# STM32WBA54 register map
File version: 1.0
CPU: CM33 r0p1, little endian, MPU, FPU, 4 interrupt priority bits
Registers are 32-bit, read-write, reset 0x0 unless marked. A register's access mark holds for its fields unless they carry their own. Offsets are from the block's base; [hi:lo] are bit positions; {n}, {i} and the like mark numbered series.

## HSEM — Hardware semaphore
Base 0x420C1C00
Same registers: SEC_HSEM 0x520C1C00
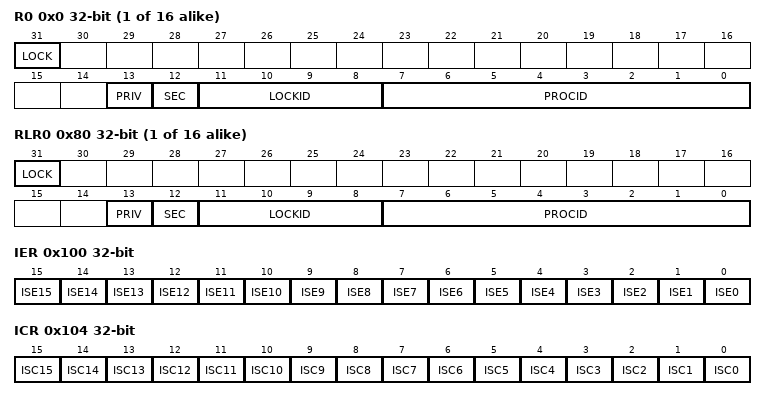
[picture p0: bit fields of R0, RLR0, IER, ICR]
{0x0+4i} R{i} (i=0..15) — HSEM register HSEM_R{i}
  [31] LOCK — Lock indication This bit can be written and read by software.
  [13] PRIV — Semaphore privilege Written by software - When the semaphore is free and the LOCK bit is at the same time written to 1, and the LOCKID matches the AHB bus master ID, SEC and PRIV matches the AHB bus master definition. - When the semaphore is unlocked (LOCK written to 0 and AHB bus master ID matched LOCKID, SEC and PRIV matches the AHB bus master definition, the PRIV is cleared to 0. - When the semaphore is unlocked (LOCK bit written to 0 and AHB bus master ID does not match LOCKID and/or SEC or PRIV do not match AHB bus master definition, the PRIV is not affected. - Write when LOCK bit is already 1 (semaphore locked), the PRIV is not affected. - An authorized read returns the stored PRIV value.
  [12] SEC — Semaphore secure Written by software - When the semaphore is free and the LOCK bit is at the same time written to 1, and the LOCKID matches the AHB bus master ID, SEC and PRIV matches the AHB bus master definition. - When the semaphore is unlocked (LOCK written to 0 and AHB bus master ID matched LOCKID, SEC and PRIV matches the AHB bus master definition, the SEC is cleared to 0. - When the semaphore is unlocked (LOCK bit written to 0 and AHB bus master ID does not match LOCKID and/or SEC or PRIV do not match AHB bus master definition, the SEC is not affected. - Write when LOCK bit is already 1 (semaphore locked), the SEC is not affected. - An authorized read returns the stored SEC value.
  [11:8] LOCKID — Semaphore LOCKID Written by software - When the semaphore is free and the LOCK bit is at the same time written to 1 and the LOCKID matches the AHB bus master ID, SEC and PRIV matches the AHB bus master protection. - When the semaphore is unlocked (LOCK written to 0 and AHB bus master ID matched LOCKID, SEC and PRIV matches the AHB bus master protection, the LOCKID is cleared to 0. - When the semaphore is unlocked (LOCK bit written to 0 or AHB bus master ID does not match LOCKID and/or SEC or PRIV do not match AHB bus master protection, the LOCKID is not affected. - Write when LOCK bit is already 1 (semaphore locked), the LOCKID is not affected. - An authorized read returns the stored LOCKID value.
  [7:0] PROCID — Semaphore PROCID Written by software -When the semaphore is free and the LOCK is written to 1, and the LOCKID matches the AHB bus master ID, SEC and PRIV matches the AHB bus master definition, PROCID is set to the written data. - When the semaphore is unlocked, LOCK written to 0 and AHB bus master ID matched LOCKID, SEC and PRIV matches the AHB bus master protection, the PROCID is cleared to 0. - When the semaphore is unlocked, LOCK bit written to 0 and AHB bus master ID does not match LOCKID and/or SEC or PRIV do not match the AHB bus master definition, the PROCID is not affected. - Write when LOCK bit is already 1 (semaphore locked), the PROCID is not affected. - An authorized read returns the stored PROCID value.
{0x80+4i} RLR{i} (i=0..15) ro — Semaphore {i} read lock register
  [31] LOCK — Lock indication This bit is read only by software at this address. - When the semaphore is free: A read with a valid AHB bus master ID and SEC and PRIV locks the semaphore and returns 1. - When the semaphore is locked: A read with a valid AHB bus master ID and SEC and PRIV returns 1 (the LOCKID and SEC and PRIV and PROCID reflect the already locked semaphore information).
  [13] PRIV — Semaphore privilege This field is read only by software at this address. - When the semaphore is free: A read with a valid AHB bus master ID and SEC and PRIV locks the semaphore and hardware sets the PRIV to the valid AHB bus master privileged definition. - When the semaphore is locked: A read with a valid AHB bus master ID and SEC and PRIV returns the PRIV of the AHB bus master that has locked the semaphore.
  [12] SEC — Semaphore secure. This field is read only by software at this address. - When the semaphore is free: A read with a valid AHB bus master ID and SEC and PRIV locks the semaphore and hardware sets the SEC to the valid AHB bus master security definition. - When the semaphore is locked: A read with a valid AHB bus master ID and SEC and PRIV returns the SEC of the AHB bus master that has locked the semaphore.
  [11:8] LOCKID — Semaphore LOCKID This field is read only by software at this address. On a read, when the semaphore is free, the hardware sets the LOCKID to the AHB bus master ID reading the semaphore. The LOCKID of the AHB bus master locking the semaphore is read. On a read when the semaphore is locked, this field returns the LOCKID of the AHB bus master that has locked the semaphore.
  [7:0] PROCID — Semaphore processor ID This field is read only by software at this address. - On a read when the semaphore is free: A read with a valid AHB bus master ID and SEC and PRIV locks the semaphore and hardware sets the PROCID to 0. - When the semaphore is locked: A read with a valid AHB bus master ID and SEC and PRIV returns the PROCID of the AHB bus master that has locked the semaphore.
0x100 IER access not given — HSEM non-secure interrupt enable register
  [n] ISE{n} (n=0..15) — Interrupt semaphore {n} enable bit
0x104 ICR access not given — HSEM non-secure interrupt clear register
  [n] ISC{n} (n=0..15) — Interrupt semaphore {n} clear bit
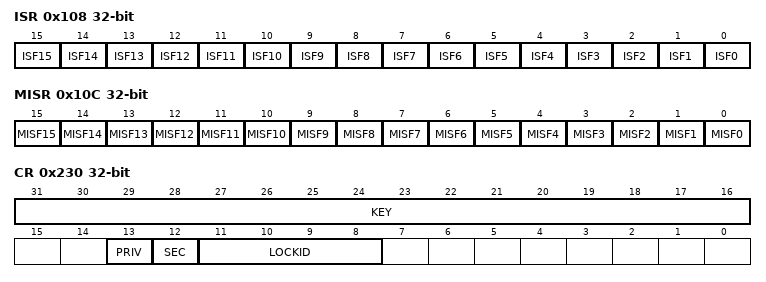
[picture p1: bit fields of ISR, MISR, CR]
0x108 ISR access not given — HSEM non-secure interrupt status register
  [n] ISF{n} (n=0..15) — Interrupt semaphore {n} status bit before enable (mask)
0x10C MISR access not given — HSEM non-secure interrupt status register
  [n] MISF{n} (n=0..15) — Masked interrupt semaphore {n} status bit after enable (mask)
0x180 SIER — HSEM secure interrupt enable register
  [15:0] SISE — Secure interrupt semaphore x enable bit This bit is read and written by software. When semaphore x PRIVx is disabled, bit x can be accessed with secure privilege and secure unprivileged access. When semaphore x PRIVx is enabled, bit x can be accessed only with secure privilege access. secure unprivileged write to this bit is discarded, secure unprivileged read return 0 value.
0x184 SICR — HSEM secure interrupt clear register
  [15:0] SISC — Secure interrupt semaphore x clear bit This bit is written by software, and is always read 0. When semaphore x PRIVx is disabled, bit x can be accessed with secure privilege and secure unprivileged access. When semaphore x PRIVx is enabled, bit x can be accessed only with secure privilege access. Secure unprivileged write to this bit is discarded.
0x188 SISR ro — HSEM secure interrupt status register
  [15:0] SISF — Secure interrupt semaphore x status bit before enable (mask) This bit is set by hardware and read only by software. Bit is cleared by software writing the corresponding HSEM_SCnICR bit x. When semaphore x PRIVx is disabled, bit x can be accessed with secure privilege and secure unprivileged access. When semaphore x PRIVx is enabled, bit x can be accessed only with secure privilege access. Secure unprivileged read return 0 value.
0x18C MSISR ro — HSEM secure masked interrupt status register
  [15:0] SMISF — Secure masked interrupt semaphore x status bit after enable (mask) This bit is set by hardware and read only by software. Bit is cleared by software writing the corresponding HSEM_SCnICR bit x. Bit is read as 0 when semaphore x status is masked in HSEM_SCnIER bit x. When semaphore x PRIVx is disabled, bit x can be accessed with secure privilege and secure unprivileged access. When semaphore x PRIVx is enabled, bit x can be accessed only with secure privilege access. Secure unprivileged read return 0 value.
0x200 SECCFGR — HSEM security configuration register
  [15:0] SEC — Semaphore x security attribute This bit is set and cleared by software.
0x210 PRIVCFGR — HSEM privilege configuration register
  [15:0] PRIV — Semaphore x privilege attribute This bit is set and cleared by software. When semaphore x SECx is disabled, bit x can be write accessed with secure privileged and non-secure privileged access. When semaphore x SECx is enabled, bit x can only be write accessed with secure privilege access. Non-secure privileged write access is discarded. Both secure and non-secure read return the register bit x value
0x230 CR wo — HSEM clear register
  [31:16] KEY — Semaphore clear key This field can be written by software and is always read 0. If this key value does not match HSEM_KEYR.KEY, semaphores are not affected. If this key value matches HSEM_KEYR.KEY, all semaphores matching the LOCKID are cleared to the free state.
  [13] PRIV — PRIV value of semaphores to be cleared. This field can be written by software, is always read 0. Indicates the PRIV for which the CID semaphores are cleared when writing the HSEM_CR.
  [12] SEC — SEC value of semaphores to be cleared. This field can be written by software, is always read 0. Indicates the SEC for which the CID semaphores are cleared when writing the HSEM_CR
  [11:8] LOCKID — LOCKID of semaphores to be cleared This field can be written by software and is always read 0. This field indicates the LOCKID for which the semaphores are cleared when writing the HSEM_CR.
0x234 KEYR — HSEM interrupt clear register
  [31:16] KEY — Semaphore clear key This field can be written and read by software. Key value to match when clearing semaphores.
